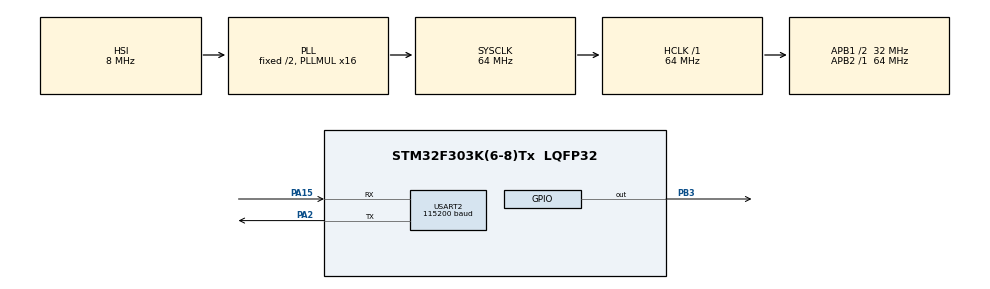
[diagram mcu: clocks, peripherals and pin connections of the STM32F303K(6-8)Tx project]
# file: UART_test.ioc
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Mcu.Family=STM32F3
Mcu.Name=STM32F303K(6-8)Tx
Mcu.Package=LQFP32
NVIC.PriorityGroup=NVIC_PRIORITYGROUP_4
PA15.Mode=Asynchronous
PA15.Signal=USART2_RX
PA2.Mode=Asynchronous
PA2.Signal=USART2_TX
PB3.Signal=GPIO_Output
ProjectManager.HeapSize=0x200
ProjectManager.StackSize=0x400
ProjectManager.TargetToolchain=STM32CubeIDE
RCC.AHBFreq_Value=64000000
RCC.APB1CLKDivider=RCC_HCLK_DIV2
RCC.APB1Freq_Value=32000000
RCC.APB1TimFreq_Value=64000000
RCC.APB2Freq_Value=64000000
RCC.APB2TimFreq_Value=64000000
RCC.CortexFreq_Value=64000000
RCC.HCLKFreq_Value=64000000
RCC.HSE_VALUE=8000000
RCC.HSI_VALUE=8000000
RCC.PLLMUL=RCC_PLL_MUL16
RCC.SYSCLKFreq_VALUE=64000000
RCC.SYSCLKSourceVirtual=RCC_SYSCLKSOURCE_PLLCLK
USART2.BaudRate=115200
USART2.VirtualMode-Asynchronous=VM_ASYNC
board=custom

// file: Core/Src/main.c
/* USER CODE BEGIN Header */
/**
  ******************************************************************************
  * @file           : main.c
  * @brief          : Main program body
  ******************************************************************************
  * @attention
  *
  * Copyright (c) 2022 STMicroelectronics.
  * All rights reserved.
  *
  * This software is licensed under terms that can be found in the LICENSE file
  * in the root directory of this software component.
  * If no LICENSE file comes with this software, it is provided AS-IS.
  *
  ******************************************************************************
  */
/* USER CODE END Header */
#include "main.h"

/* USER CODE BEGIN Includes */
#include<stdio.h>
/* USER CODE END Includes */

 UART_HandleTypeDef huart2;

void SystemClock_Config(void);
static void MX_GPIO_Init(void);
static void MX_USART2_UART_Init(void);

int main(void)
{

  /* MCU Configuration--------------------------------------------------------*/

  /* Reset of all peripherals, Initializes the Flash interface and the Systick. */
  HAL_Init();

  /* Configure the system clock */
  SystemClock_Config();

  /* Initialize all configured peripherals */
  MX_GPIO_Init();
  MX_USART2_UART_Init();
  /* USER CODE BEGIN 2 */
  char msg[] ="Hello STM32\r\n";
  char msg2[] ="PushButton\r\n";
  char rec1[] ="Receive1\r\n";
  char rec2[] ="Receive2\r\n";
  char nonans[] ="Not Understand \r\n";

  char rev;

  HAL_UART_Transmit(&huart2,(uint8_t *)msg,sizeof(msg),3000);

  /* USER CODE END 2 */

  /* Infinite loop */
  while (1)
  {

    /* USER CODE BEGIN 3 */
	  if(HAL_UART_Receive(&huart2, &rev, 1, 1000)==HAL_OK){
	               switch(rev)
	                       {
	               case '1':
	                           HAL_GPIO_WritePin(GPIOB, GPIO_PIN_3,1);
	                           HAL_UART_Transmit(&huart2,(uint8_t *)rec1,sizeof(rec1),3000);
	                           break;
	               case '2':
	                           HAL_GPIO_WritePin(GPIOB, GPIO_PIN_3,0);
	                           HAL_UART_Transmit(&huart2,(uint8_t *)rec2,sizeof(rec2),3000);
	                           break;
	               default:
	                           HAL_GPIO_TogglePin(GPIOB, GPIO_PIN_3);
	                           HAL_UART_Transmit(&huart2,(uint8_t *)nonans,sizeof(nonans),3000);
	                           break;
	                       }
	           }
  }
  /* USER CODE END 3 */
}

void SystemClock_Config(void)
{
  RCC_OscInitTypeDef RCC_OscInitStruct = {0};
  RCC_ClkInitTypeDef RCC_ClkInitStruct = {0};

  /** Initializes the RCC Oscillators according to the specified parameters
  * in the RCC_OscInitTypeDef structure.
  */
  RCC_OscInitStruct.OscillatorType = RCC_OSCILLATORTYPE_HSI;
  RCC_OscInitStruct.HSIState = RCC_HSI_ON;
  RCC_OscInitStruct.HSICalibrationValue = RCC_HSICALIBRATION_DEFAULT;
  RCC_OscInitStruct.PLL.PLLState = RCC_PLL_ON;
  RCC_OscInitStruct.PLL.PLLSource = RCC_PLLSOURCE_HSI;
  RCC_OscInitStruct.PLL.PLLMUL = RCC_PLL_MUL16;
  if (HAL_RCC_OscConfig(&RCC_OscInitStruct) != HAL_OK)
  {
    Error_Handler();
  }

  /** Initializes the CPU, AHB and APB buses clocks
  */
  RCC_ClkInitStruct.ClockType = RCC_CLOCKTYPE_HCLK|RCC_CLOCKTYPE_SYSCLK
                              |RCC_CLOCKTYPE_PCLK1|RCC_CLOCKTYPE_PCLK2;
  RCC_ClkInitStruct.SYSCLKSource = RCC_SYSCLKSOURCE_PLLCLK;
  RCC_ClkInitStruct.AHBCLKDivider = RCC_SYSCLK_DIV1;
  RCC_ClkInitStruct.APB1CLKDivider = RCC_HCLK_DIV2;
  RCC_ClkInitStruct.APB2CLKDivider = RCC_HCLK_DIV1;

  if (HAL_RCC_ClockConfig(&RCC_ClkInitStruct, FLASH_LATENCY_2) != HAL_OK)
  {
    Error_Handler();
  }
}

static void MX_USART2_UART_Init(void)
{

  huart2.Instance = USART2;
  huart2.Init.BaudRate = 115200;
  huart2.Init.WordLength = UART_WORDLENGTH_8B;
  huart2.Init.StopBits = UART_STOPBITS_1;
  huart2.Init.Parity = UART_PARITY_NONE;
  huart2.Init.Mode = UART_MODE_TX_RX;
  huart2.Init.HwFlowCtl = UART_HWCONTROL_NONE;
  huart2.Init.OverSampling = UART_OVERSAMPLING_16;
  huart2.Init.OneBitSampling = UART_ONE_BIT_SAMPLE_DISABLE;
  huart2.AdvancedInit.AdvFeatureInit = UART_ADVFEATURE_NO_INIT;
  if (HAL_UART_Init(&huart2) != HAL_OK)
  {
    Error_Handler();
  }

}

static void MX_GPIO_Init(void)
{
  GPIO_InitTypeDef GPIO_InitStruct = {0};

  /* GPIO Ports Clock Enable */
  __HAL_RCC_GPIOA_CLK_ENABLE();
  __HAL_RCC_GPIOB_CLK_ENABLE();

  /*Configure GPIO pin Output Level */
  HAL_GPIO_WritePin(GPIOB, GPIO_PIN_3, GPIO_PIN_RESET);

  /*Configure GPIO pin : PB3 */
  GPIO_InitStruct.Pin = GPIO_PIN_3;
  GPIO_InitStruct.Mode = GPIO_MODE_OUTPUT_PP;
  GPIO_InitStruct.Pull = GPIO_NOPULL;
  GPIO_InitStruct.Speed = GPIO_SPEED_FREQ_LOW;
  HAL_GPIO_Init(GPIOB, &GPIO_InitStruct);

}

void Error_Handler(void)
{
  __disable_irq();
  while (1)
  {
  }
}
